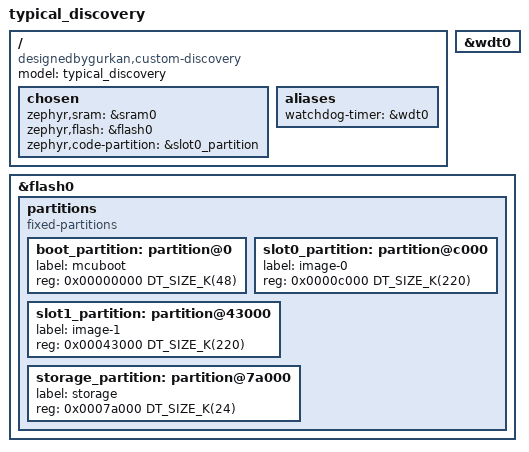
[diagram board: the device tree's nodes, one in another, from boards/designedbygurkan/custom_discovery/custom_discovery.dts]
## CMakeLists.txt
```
cmake_minimum_required(VERSION 3.20.0)

get_filename_component(ZEPHYR_CIRCULAR_BUFFER_MODULE_DIR
  ${CMAKE_CURRENT_LIST_DIR}/zephyr_circular_buffer
  ABSOLUTE
)

list(APPEND ZEPHYR_EXTRA_MODULES ${ZEPHYR_CIRCULAR_BUFFER_MODULE_DIR})

find_package(Zephyr REQUIRED HINTS $ENV{ZEPHYR_BASE})

project(Heart_monitor)

target_sources(app PRIVATE src/main.c src/watchdog.c src/system_reset_reason.c)
zephyr_library_include_directories(src/include)
```

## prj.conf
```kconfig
CONFIG_LOG=y
CONFIG_CONSOLE=y
CONFIG_USE_SEGGER_RTT=y
CONFIG_LOG_BACKEND_RTT=y
CONFIG_RTT_CONSOLE=y
CONFIG_ENTROPY_GENERATOR=y


CONFIG_CLOCK_CONTROL=y
CONFIG_CLOCK_CONTROL_NRF_K32SRC_XTAL=y

CONFIG_WATCHDOG=y
CONFIG_REBOOT=y
CONFIG_CIRCULAR_BUFFER=y
CONFIG_CIRCULAR_BUFFER_LOG_LEVEL=0
# CONFIG_LINKED_LIST=y
CONFIG_STATIC_ARRAY=y
CONFIG_CIRCULAR_BUFFER_SIZE=30
```

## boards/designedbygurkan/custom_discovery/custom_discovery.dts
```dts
/dts-v1/;
#include <nordic/nrf52833_qiaa.dtsi>
#include "custom_discovery-pinctrl.dtsi"

/ {
	model = "typical_discovery";
	compatible = "designedbygurkan,custom-discovery";

	chosen {
		zephyr,sram = &sram0;
		zephyr,flash = &flash0;
		zephyr,code-partition = &slot0_partition;
	};

	aliases {
		watchdog-timer=&wdt0;
	};
};

&wdt0 {
	status = "okay";
};

&flash0 {
	partitions {
		compatible = "fixed-partitions";
		#address-cells = <1>;
		#size-cells = <1>;

		boot_partition: partition@0 {
			label = "mcuboot";
			reg = <0x00000000 DT_SIZE_K(48)>;
		};

		slot0_partition: partition@c000 {
			label = "image-0";
			reg = <0x0000c000 DT_SIZE_K(220)>;
		};

		slot1_partition: partition@43000 {
			label = "image-1";
			reg = <0x00043000 DT_SIZE_K(220)>;
		};

		storage_partition: partition@7a000 {
			label = "storage";
			reg = <0x0007a000 DT_SIZE_K(24)>;
		};
	};
};
```

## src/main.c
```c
#include <stdbool.h>
#include <stdint.h>

#include <zephyr/kernel.h>
#include <zephyr/logging/log.h>
#include <zephyr/random/random.h>
#include <zephyr/sys/atomic.h>
#include <zephyr/sys/util.h>

#include "system_reset_reason.h"
#include "circular_buffer.h"
#include "watchdog.h"

LOG_MODULE_REGISTER(heart_monitor, LOG_LEVEL_INF);

#define EMA_ALPHA_MAX	256
#define THREAD_PRIORITY 4
#define PRODUCER_INTERVAL_MS 1000
#define CONSUMER_INTERVAL_MS 10000
#define EMA_ALPHA_FACTOR (64)

K_THREAD_STACK_DEFINE(producer_stack, 1024);
K_THREAD_STACK_DEFINE(consumer_stack, 1024);

static struct k_thread producer_thread;
static struct k_thread consumer_thread;

static k_tid_t producer_tid;
static k_tid_t consumer_tid;

K_MUTEX_DEFINE(buffer_mutex);
static atomic_t producer_wdt_check;
static atomic_t consumer_wdt_check;

//EMA=alpha⋅x+(1−alpha)⋅prev
// for easy divison I change ema range to 0-256
struct ema_filter { 
	uint32_t value;
	uint16_t alpha_factor; //based 256
	uint8_t initialized:1;
}ema={0,EMA_ALPHA_FACTOR,false};

static void producer_task(void *arg1, void *arg2, void *arg3);
static void consumer_task(void *arg1, void *arg2, void *arg3);

static uint8_t generate_random_sample(void)
{
	uint32_t value = sys_rand32_get();

	return (uint8_t)(44U + (value % (185U - 44U + 1U)));
}

static uint32_t ema_update(struct ema_filter *filter, uint8_t sample)
{
	uint32_t alpha = filter->alpha_factor;

	if (!filter->initialized) {
		filter->value = sample;
		filter->initialized = true;
		return filter->value;
	}

		/**
		 * calculation is alpha is a 256 based so
		 * alpha/256 so if we write every alpha to alpha/256
		 * now = alpha*sample/256 + (256-alpha/256)*prev
		 * ((alpha*sample)+(256-alpha)*prev))/256
		 */
	filter->value = ((alpha*sample)+(EMA_ALPHA_MAX-alpha)*filter->value)>>8; // 1>>8 = 256 easy division and faster

	return filter->value;
}

int main(void)
{       
	cb_err_t ret= circular_buffer_init();
	if (ret != CBUFFER_OK) {
		LOG_ERR("Failed to initialize circular buffer: %d", ret);
		return ret;
	}
	log_reset_reason();
	watchdog_configuration();
	if (producer_tid == NULL) {
		producer_tid = k_thread_create(&producer_thread, producer_stack,
					       K_THREAD_STACK_SIZEOF(producer_stack),
					       producer_task,
					       NULL, NULL, NULL,
					       K_PRIO_PREEMPT(THREAD_PRIORITY),
					       0, K_NO_WAIT);
	}

	if (consumer_tid == NULL) {
		consumer_tid = k_thread_create(&consumer_thread, consumer_stack,
					       K_THREAD_STACK_SIZEOF(consumer_stack),
					       consumer_task,
					       NULL, NULL, NULL,
					       K_PRIO_PREEMPT(THREAD_PRIORITY),
					       0, K_NO_WAIT);
	}

	while (true) {
		k_sleep(K_MSEC(1000));
		bool producer_heart_beat = atomic_get(&producer_wdt_check);
		bool consumer_heart_beat = atomic_get(&consumer_wdt_check);

		if (producer_heart_beat &&consumer_heart_beat) { // make sure all tasks are updated!
			watchdog_feed();
			atomic_cas(&producer_wdt_check,1,0);
			atomic_cas(&consumer_wdt_check,1,0);
		}
	}
}

static void producer_task(void *arg1, void *arg2, void *arg3)
{
	cb_err_t ret;
	uint8_t sample;

	ARG_UNUSED(arg1);
	ARG_UNUSED(arg2);
	ARG_UNUSED(arg3);

	while (true) {
		sample = generate_random_sample();

		k_mutex_lock(&buffer_mutex, K_FOREVER);
		ret = circular_buffer_push(sample);
		k_mutex_unlock(&buffer_mutex);
		if (ret != CBUFFER_OK) {
			LOG_ERR("Failed to push sample: %d", ret);
		}
		atomic_set(&producer_wdt_check, 1);

		k_sleep(K_MSEC(PRODUCER_INTERVAL_MS));
	}
}

static void consumer_task(void *arg1, void *arg2, void *arg3)
{
	uint8_t sample = 0U;
	uint32_t ema_value = 0U;
	size_t consumed = 0U;

	ARG_UNUSED(arg1);
	ARG_UNUSED(arg2);
	ARG_UNUSED(arg3);

	while (true) {
		k_sleep(K_MSEC(CONSUMER_INTERVAL_MS));
		k_mutex_lock(&buffer_mutex, K_FOREVER);
		while (circular_buffer_pop(&sample) == CBUFFER_OK) {
			ema_value = ema_update(&ema, sample);
			consumed++;
		}
		k_mutex_unlock(&buffer_mutex);
		atomic_set(&consumer_wdt_check, 1);
		if (consumed == 0U) {
			continue;
		}
		LOG_INF("latest EMA: %u", ema_value);
		consumed = 0U;
	}
}
```

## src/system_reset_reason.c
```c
#include <hal/nrf_power.h>
#include <zephyr/logging/log.h>
#include "system_reset_reason.h"

LOG_MODULE_REGISTER(RESET_REASON);

void log_reset_reason(){
    uint32_t reason = nrf_power_resetreas_get(NRF_POWER);
    if(reason ==0){
        LOG_INF("Reset occured unknown");
    }
    LOG_INF("Reset reason is %u",reason);
    if(reason & NRF_POWER_RESETREAS_RESETPIN_MASK){
        LOG_INF("Reset Cause: Reset pin");
    }

    if(reason & NRF_POWER_RESETREAS_DOG_MASK){
        LOG_INF("Reset Cause: WDT timeout");
    }

    if(reason & NRF_POWER_RESETREAS_SREQ_MASK){
        LOG_INF("Reset Cause: Software Reset");
    }
    if(reason & NRF_POWER_RESETREAS_LOCKUP_MASK){
        LOG_INF("Reset Cause: cpu lockup");
    }

    if(reason & NRF_POWER_RESETREAS_OFF_MASK){
        LOG_INF("Reset Cause: Wake from System OFF");
    }

    if(reason & NRF_POWER_RESETREAS_SREQ_MASK){
        LOG_INF("Reset Cause: Software Reset");
    }

    nrf_power_resetreas_clear(NRF_POWER, reason);
}
```

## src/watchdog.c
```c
#include "watchdog.h"
#include <zephyr/sys/reboot.h>
#include <zephyr/drivers/watchdog.h>
LOG_MODULE_REGISTER(watchdog_timer, LOG_LEVEL_INF);

#ifndef WDT_OPT
#define WDT_OPT 0
#endif

#ifndef WDT_MAX_WINDOW// consumer task has 10second sleep
#define WDT_MAX_WINDOW  20000U 
#endif

#ifndef WDT_MIN_WINDOW
#define WDT_MIN_WINDOW  0U
#endif


#ifndef WDT_ALLOW_CALLBACK
#define WDT_ALLOW_CALLBACK 0
#endif

static int wdt_channel_id;
const struct device *const wdt = DEVICE_DT_GET(DT_ALIAS(watchdog_timer));

#if WDT_ALLOW_CALLBACK
static void wdt_callback(const struct device *wdt_dev, int channel_id)
{
	ARG_UNUSED(wdt_dev);
	ARG_UNUSED(channel_id);
	sys_reboot(0);
}
#endif /* WDT_ALLOW_CALLBACK */


void watchdog_configuration(){
    int err;

	if (!device_is_ready(wdt)) {
		LOG_ERR("%s: device not ready.\n", wdt->name);
		return ;
	}

	struct wdt_timeout_cfg wdt_config = {

		.flags = WDT_FLAG_RESET_SOC,
		.window.min = WDT_MIN_WINDOW,
		.window.max = WDT_MAX_WINDOW,
	};

#if WDT_ALLOW_CALLBACK
	
	wdt_config.callback = wdt_callback;

	LOG_INF("Watchdog callback enabled");
#else 
	wdt_config.callback = NULL;
	LOG_INF("Watchdog callback disabled, hardware reset only");
#endif 

	wdt_channel_id = wdt_install_timeout(wdt, &wdt_config);
	if (wdt_channel_id == -ENOTSUP) {
		LOG_ERR("Watchdog callback/flags not supported, retrying without callback");
		wdt_config.callback = NULL;
		wdt_channel_id = wdt_install_timeout(wdt, &wdt_config);
	}
	if (wdt_channel_id < 0) {
		LOG_ERR("Watchdog install error: %d", wdt_channel_id);
		return ;
	}
	LOG_INF("Watchdog timeout installed on channel %d, timeout=%u ms",
		wdt_channel_id, (unsigned int)WDT_MAX_WINDOW);

	err = wdt_setup(wdt, WDT_OPT);
	if (err < 0) {
		LOG_ERR("Watchdog setup error: %d", err);
		return ;
	}
	LOG_INF("Watchdog started");
}

void watchdog_feed(){
	int err = wdt_feed(wdt, wdt_channel_id);
	LOG_INF("FEED CALLED");
	if (err < 0) {
		LOG_ERR("Watchdog feed failed: %d", err);
	}
}
```
